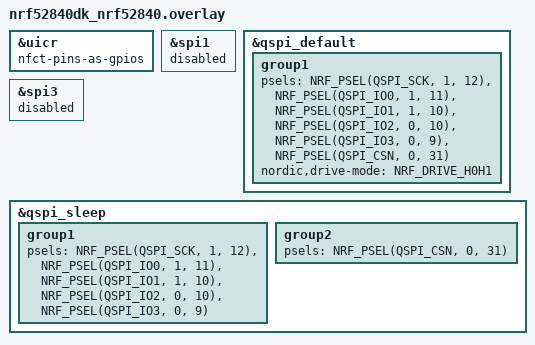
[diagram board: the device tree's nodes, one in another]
// To get started, press Ctrl+Space to bring up the completion menu and view the available nodes.

// You can also use the buttons in the sidebar to perform actions on nodes.
// Actions currently available include:

// * Enabling / disabling the node
// * Adding the bus to a bus
// * Removing the node
// * Connecting ADC channels

// For more help, browse the DeviceTree documentation at https://docs.zephyrproject.org/latest/guides/dts/index.html
// You can also visit the nRF DeviceTree extension documentation at https://docs.nordicsemi.com/bundle/nrf-connect-vscode/page/guides/ncs_configure_app.html#devicetree-support-in-the-extension
&uicr {
    nfct-pins-as-gpios;
};
&spi1 {
    status = "disabled";
};

&qspi_default {
    group1 {
        psels = <NRF_PSEL(QSPI_SCK, 1, 12)>,
                <NRF_PSEL(QSPI_IO0, 1, 11)>,
                <NRF_PSEL(QSPI_IO1, 1, 10)>,
                <NRF_PSEL(QSPI_IO2, 0, 10)>,
                <NRF_PSEL(QSPI_IO3, 0, 9)>,
                <NRF_PSEL(QSPI_CSN, 0, 31)>;
        nordic,drive-mode = <NRF_DRIVE_H0H1>;
    };
};

&spi3 {
    status = "disabled";
};

&qspi_sleep {
    group1 {
        psels = <NRF_PSEL(QSPI_SCK, 1, 12)>,
                <NRF_PSEL(QSPI_IO0, 1, 11)>,
                <NRF_PSEL(QSPI_IO1, 1, 10)>,
                <NRF_PSEL(QSPI_IO2, 0, 10)>,
                <NRF_PSEL(QSPI_IO3, 0, 9)>;
    };

    group2 {
        psels = <NRF_PSEL(QSPI_CSN, 0, 31)>;
    };
};
